# MIMXRT1011 register map
Vendor: nxp.com; File version: 1.0
CPU: CM7 r0p1, little endian, MPU, FPU, VTOR, 4 interrupt priority bits
Registers are 32-bit, read-write, reset 0x0 unless marked. A register's access mark holds for its fields unless they carry their own. Offsets are from the block's base; [hi:lo] are bit positions; {n}, {i} and the like mark numbered series; 'fields as' and 'values as' point back to an identical list.

## IOMUXC_GPR
Base 0x400AC000; register names take the prefix IOMUXC_GPR_
0x00 GPR0 ro — GPR0 General Purpose Register
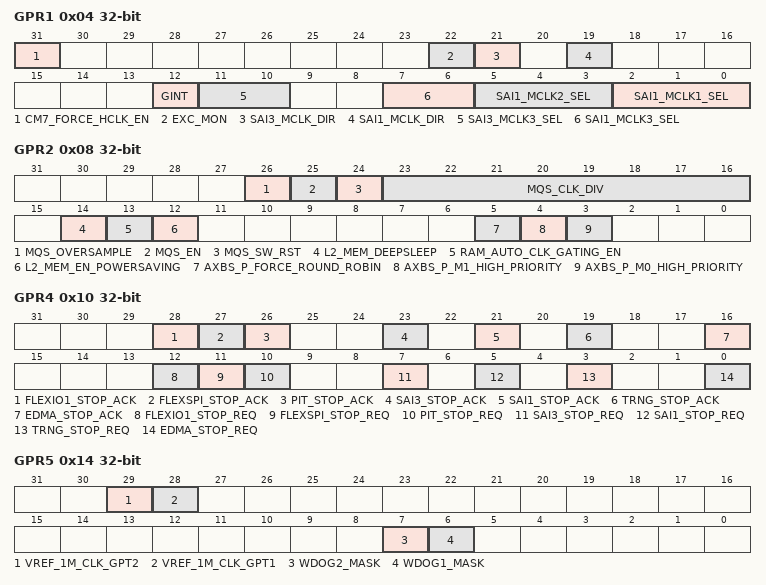
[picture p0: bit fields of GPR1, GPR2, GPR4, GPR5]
0x04 GPR1 — GPR1 General Purpose Register
  [31] CM7_FORCE_HCLK_EN — Arm CM7 platform AHB clock enable
    0=AHB clock is not running (gated) when CM7 is sleeping and TCM is not accessible; 1=AHB clock is running (enabled) when CM7 is sleeping and TCM is accessible
  [22] EXC_MON — Exclusive monitor response select of illegal command
    0=OKAY response; 1=SLVError response
  [21] SAI3_MCLK_DIR — sai3.MCLK signal direction control
    0=sai3.MCLK is input signal; 1=sai3.MCLK is output signal
  [19] SAI1_MCLK_DIR — sai1.MCLK signal direction control
    0=sai1.MCLK is input signal; 1=sai1.MCLK is output signal
  [12] GINT — Global Interrupt
    0=Global interrupt request is not asserted; 1=Global interrupt request is asserted
  [11:10] SAI3_MCLK3_SEL — SAI3 MCLK3 source select
    0=ccm.spdif0_clk_root; 1=SPDIF_EXT_CLK; 2=spdif.spdif_srclk; 3=spdif.spdif_outclock
  [7:6] SAI1_MCLK3_SEL — SAI1 MCLK3 source select
    values as SAI3_MCLK3_SEL
  [5:3] SAI1_MCLK2_SEL — SAI1 MCLK2 source select
    0=ccm.ssi1_clk_root; 2=ccm.ssi3_clk_root; 3=iomux.sai1_ipg_clk_sai_mclk; 5=iomux.sai3_ipg_clk_sai_mclk
  [2:0] SAI1_MCLK1_SEL — SAI1 MCLK1 source select
    values as SAI1_MCLK2_SEL
0x08 GPR2 — GPR2 General Purpose Register
  [26] MQS_OVERSAMPLE — Medium Quality Sound (MQS) Oversample
    0=32; 1=64
  [25] MQS_EN — MQS enable.
    0=Disable MQS; 1=Enable MQS
  [24] MQS_SW_RST — MQS software reset
    0=Exit software reset for MQS; 1=Enable software reset for MQS
  [23:16] MQS_CLK_DIV — Divider ratio control for mclk from hmclk
    0=mclk frequency = hmclk frequency; 1=mclk frequency = 1/2 * hmclk frequency; 2=mclk frequency = 1/3 * hmclk frequency; 255=mclk frequency = 1/256 * hmclk frequency
  [14] L2_MEM_DEEPSLEEP — This bit controls how memory (OCRAM) enters Deep Sleep mode (shutdown periphery power, but maintain memory contents, outputs of memory are pulled low
    0=No force sleep control supported, memory deep sleep mode only entered when whole system in stop mode (OCRAM in normal mode); 1=Force memory into deep sleep mode (OCRAM in power saving mode)
  [13] RAM_AUTO_CLK_GATING_EN — Automatically gate off RAM clock when RAM is not accessed.
    0=disable automatically gate off RAM clock; 1=enable automatically gate off RAM clock
  [12] L2_MEM_EN_POWERSAVING — Enable power saving features on L2 memory
    0=Enters power saving mode only when chip is in SUSPEND mode; 1=Controlled by L2_MEM_DEEPSLEEP bitfield
  [5] AXBS_P_FORCE_ROUND_ROBIN — Force Round Robin in AXBS_P. This bit can override master M0 M1 high priority configuration.
    0=AXBS_P masters are not arbitored in round robin, depending on M0/M1 master priority settings; 1=AXBS_P masters are arbitored in round robin
  [4] AXBS_P_M1_HIGH_PRIORITY — AXBS_P M1 master has higher priority.Do not set both M1 and M0 to high priority.
    0=AXBS_P M1 master does not have high priority; 1=AXBS_P M1 master has high priority
  [3] AXBS_P_M0_HIGH_PRIORITY — AXBS_P M0 master has higher priority.Do not set both M1 and M0 to high priority.
    0=AXBS_P M0 master doesn't have high priority; 1=AXBS_P M0 master has high priority
0x0C GPR3 reset 0xFF0 — GPR3 General Purpose Register
  [4] DCP_KEY_SEL — Select 128-bit DCP key from 256-bit key from SNVS Master Key
    0=Select [127:0] from SNVS Master Key as DCP key; 1=Select [255:128] from SNVS Master Key as DCP key
0x10 GPR4 — GPR4 General Purpose Register
  [28] FLEXIO1_STOP_ACK ro — FLEXIO1 stop acknowledge
    0=FLEXIO1 stop acknowledge is not asserted; 1=FLEXIO1 stop acknowledge is asserted
  [27] FLEXSPI_STOP_ACK ro — FLEXSPI stop acknowledge
    0=FLEXSPI stop acknowledge is not asserted; 1=FLEXSPI stop acknowledge is asserted
  [26] PIT_STOP_ACK ro — PIT stop acknowledge
    0=PIT stop acknowledge is not asserted; 1=PIT stop acknowledge is asserted
  [23] SAI3_STOP_ACK ro — SAI3 stop acknowledge
    0=SAI3 stop acknowledge is not asserted; 1=SAI3 stop acknowledge is asserted
  [21] SAI1_STOP_ACK ro — SAI1 stop acknowledge
    0=SAI1 stop acknowledge is not asserted; 1=SAI1 stop acknowledge is asserted
  [19] TRNG_STOP_ACK ro — TRNG stop acknowledge
    0=TRNG stop acknowledge is not asserted; 1=TRNG stop acknowledge is asserted
  [16] EDMA_STOP_ACK ro — EDMA stop acknowledge. This is a status (read-only) bit
    0=EDMA stop acknowledge is not asserted; 1=EDMA stop acknowledge is asserted (EDMA is in STOP mode)
  [12] FLEXIO1_STOP_REQ — FlexIO1 stop request.
    0=stop request off; 1=stop request on
  [11] FLEXSPI_STOP_REQ — FlexSPI stop request.
    0=stop request off; 1=stop request on
  [10] PIT_STOP_REQ — PIT stop request.
    0=stop request off; 1=stop request on
  [7] SAI3_STOP_REQ — SAI3 stop request.
    0=stop request off; 1=stop request on
  [5] SAI1_STOP_REQ — SAI1 stop request.
    0=stop request off; 1=stop request on
  [3] TRNG_STOP_REQ — TRNG stop request.
    0=stop request off; 1=stop request on
  [0] EDMA_STOP_REQ — EDMA stop request.
    0=stop request off; 1=stop request on
0x14 GPR5 — GPR5 General Purpose Register
  [29] VREF_1M_CLK_GPT2 — GPT2 1 MHz clock source select
    0=GPT2 ipg_clk_highfreq driven by IPG_PERCLK; 1=GPT2 ipg_clk_highfreq driven by anatop 1 MHz clock
  [28] VREF_1M_CLK_GPT1 — GPT1 1 MHz clock source select
    0=GPT1 ipg_clk_highfreq driven by IPG_PERCLK; 1=GPT1 ipg_clk_highfreq driven by anatop 1 MHz clock
  [7] WDOG2_MASK — WDOG2 Timeout Mask
    0=WDOG2 Timeout behaves normally; 1=WDOG2 Timeout is masked
  [6] WDOG1_MASK — WDOG1 Timeout Mask
    0=WDOG1 Timeout behaves normally; 1=WDOG1 Timeout is masked
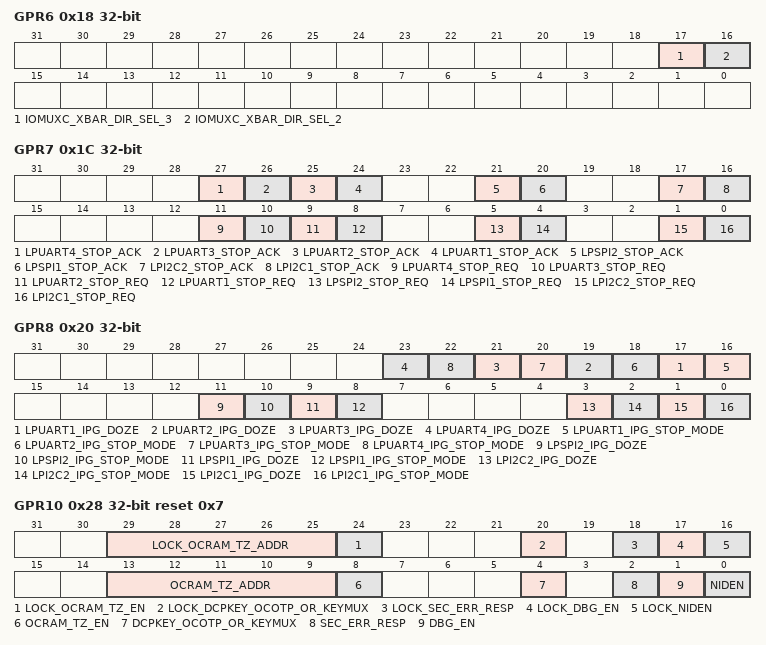
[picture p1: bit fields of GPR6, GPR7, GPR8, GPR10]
0x18 GPR6 — GPR6 General Purpose Register
  [17] IOMUXC_XBAR_DIR_SEL_3 — IOMUXC XBAR_INOUT3 function direction select
    0=XBAR_INOUT as input; 1=XBAR_INOUT as output
  [16] IOMUXC_XBAR_DIR_SEL_2 — IOMUXC XBAR_INOUT2 function direction select
    0=XBAR_INOUT as input; 1=XBAR_INOUT as output
0x1C GPR7 — GPR7 General Purpose Register
  [27] LPUART4_STOP_ACK ro — LPUART4 stop acknowledge
    0=stop acknowledge is not asserted; 1=stop acknowledge is asserted
  [26] LPUART3_STOP_ACK ro — LPUART3 stop acknowledge
    values as LPUART4_STOP_ACK
  [25] LPUART2_STOP_ACK ro — LPUART1 stop acknowledge
    values as LPUART4_STOP_ACK
  [24] LPUART1_STOP_ACK ro — LPUART1 stop acknowledge
    values as LPUART4_STOP_ACK
  [21] LPSPI2_STOP_ACK ro — LPSPI2 stop acknowledge
    values as LPUART4_STOP_ACK
  [20] LPSPI1_STOP_ACK ro — LPSPI1 stop acknowledge
    values as LPUART4_STOP_ACK
  [17] LPI2C2_STOP_ACK ro — LPI2C2 stop acknowledge
    values as LPUART4_STOP_ACK
  [16] LPI2C1_STOP_ACK ro — LPI2C1 stop acknowledge
    0=stop acknowledge is not asserted; 1=stop acknowledge is asserted (the module is in Stop mode)
  [11] LPUART4_STOP_REQ — LPUART4 stop request
    0=stop request off; 1=stop request on
  [10] LPUART3_STOP_REQ — LPUART3 stop request
    0=stop request off; 1=stop request on
  [9] LPUART2_STOP_REQ — LPUART1 stop request
    0=stop request off; 1=stop request on
  [8] LPUART1_STOP_REQ — LPUART1 stop request
    0=stop request off; 1=stop request on
  [5] LPSPI2_STOP_REQ — LPSPI2 stop request
    0=stop request off; 1=stop request on
  [4] LPSPI1_STOP_REQ — LPSPI1 stop request
    0=stop request off; 1=stop request on
  [1] LPI2C2_STOP_REQ — LPI2C2 stop request
    0=stop request off; 1=stop request on
  [0] LPI2C1_STOP_REQ — LPI2C1 stop request
    0=stop request off; 1=stop request on
0x20 GPR8 — GPR8 General Purpose Register
  [2n+15] LPUART{n}_IPG_DOZE (n=1..4) — LPUART{n} ipg_doze mode
    0=not in doze mode; 1=in doze mode
  [2n+14] LPUART{n}_IPG_STOP_MODE (n=1..4) — LPUART{n} stop mode selection, cannot change when ipg_stop is asserted.
    0=the module is functional in Stop mode; 1=the module is NOT functional in Stop mode, when this bit is equal to 1 and ipg_stop is asserted
  [11] LPSPI2_IPG_DOZE — LPSPI2 ipg_doze mode
    0=not in doze mode; 1=in doze mode
  [10] LPSPI2_IPG_STOP_MODE — LPSPI2 stop mode selection, cannot change when ipg_stop is asserted.
    values as LPUART1_IPG_STOP_MODE
  [9] LPSPI1_IPG_DOZE — LPSPI1 ipg_doze mode
    0=not in doze mode; 1=in doze mode
  [8] LPSPI1_IPG_STOP_MODE — LPSPI1 stop mode selection, cannot change when ipg_stop is asserted.
    values as LPUART1_IPG_STOP_MODE
  [3] LPI2C2_IPG_DOZE — LPI2C2 ipg_doze mode
    0=not in doze mode; 1=in doze mode
  [2] LPI2C2_IPG_STOP_MODE — LPI2C2 stop mode selection, cannot change when ipg_stop is asserted.
    values as LPUART1_IPG_STOP_MODE
  [1] LPI2C1_IPG_DOZE — LPI2C1 ipg_doze mode
    0=not in doze mode; 1=in doze mode
  [0] LPI2C1_IPG_STOP_MODE — LPI2C1 stop mode selection, cannot change when ipg_stop is asserted.
    values as LPUART1_IPG_STOP_MODE
0x24 GPR9 ro — GPR9 General Purpose Register
0x28 GPR10 reset 0x7 — GPR10 General Purpose Register
  [29:25] LOCK_OCRAM_TZ_ADDR — Lock OCRAM_TZ_ADDR field for changes
    0=Field is not locked; 1=Field is locked (read access only)
  [24] LOCK_OCRAM_TZ_EN — Lock OCRAM_TZ_EN field for changes
    0=Field is not locked; 1=Field is locked (read access only)
  [20] LOCK_DCPKEY_OCOTP_OR_KEYMUX — Lock DCP Key OCOTP/Key MUX selection bit
    0=Field is not locked; 1=Field is locked (read access only)
  [18] LOCK_SEC_ERR_RESP — Lock SEC_ERR_RESP field for changes
    0=Field is not locked; 1=Field is locked (read access only)
  [17] LOCK_DBG_EN — Lock DBG_EN field for changes
    0=Field is not locked; 1=Field is locked (read access only)
  [16] LOCK_NIDEN — Lock NIDEN field for changes
    0=Field is not locked; 1=Field is locked (read access only)
  [13:9] OCRAM_TZ_ADDR — OCRAM TrustZone (TZ) start address
  [8] OCRAM_TZ_EN — OCRAM TrustZone (TZ) enable.
    0=The TrustZone feature is disabled. Entire OCRAM space is available for all access types (secure/non-secure/user/supervisor).; 1=The TrustZone feature is enabled. Access to address in the range specified by [ENDADDR:STARTADDR] follows the execution mode access policy described in CSU chapter.
  [4] DCPKEY_OCOTP_OR_KEYMUX — DCP Key selection bit.
    0=Select key from SNVS Master Key; 1=Select key from OCOTP (SW_GP2)
  [2] SEC_ERR_RESP — Security error response enable for all security gaskets (on both AHB and AXI buses)
    0=OKEY response; 1=SLVError (default)
  [1] DBG_EN — Arm invasive debug enable
    0=Debug turned off; 1=Debug enabled (default)
  [0] NIDEN — Arm non-secure (non-invasive) debug enable
    0=Debug turned off; 1=Debug enabled (default)
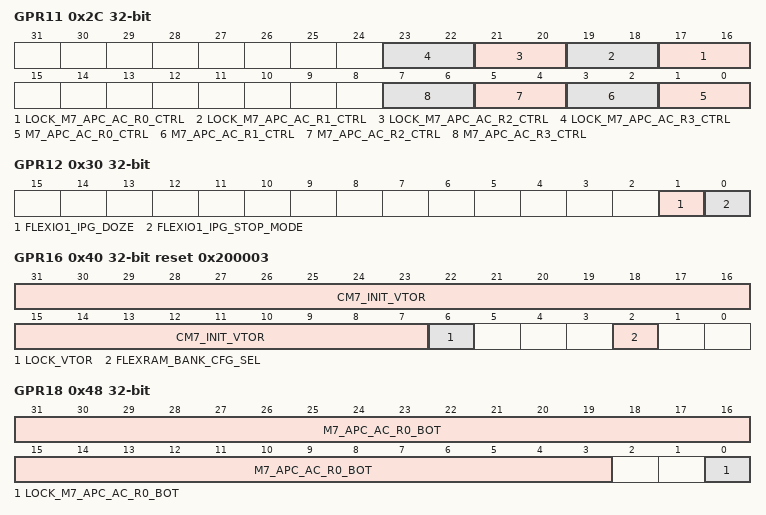
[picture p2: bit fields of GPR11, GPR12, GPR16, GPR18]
0x2C GPR11 — GPR11 General Purpose Register
  [2n+17:2n+16] LOCK_M7_APC_AC_R{n}_CTRL (n=0..3) — Lock M7_APC_AC_R{n}_CTRL field for changes
  [2n+1:2n] M7_APC_AC_R{n}_CTRL (n=0..3) — Access control of memory region-{n}
    0=No access protection; 1=M7 debug protection enabled
0x30 GPR12 — GPR12 General Purpose Register
  [1] FLEXIO1_IPG_DOZE — FLEXIO1 ipg_doze mode
    0=FLEXIO1 is not in doze mode; 1=FLEXIO1 is in doze mode
  [0] FLEXIO1_IPG_STOP_MODE — FlexIO1 stop mode selection. Cannot change when ipg_stop is asserted.
    0=FlexIO1 is functional in Stop mode; 1=When this bit is equal to 1'b1 and ipg_stop is asserted, FlexIO1 is not functional in Stop mode
0x34 GPR13 — GPR13 General Purpose Register
  [13] CACHE_USB — USB block cacheable attribute value of AXI transactions
    0=Cacheable attribute is off for read/write transactions; 1=Cacheable attribute is on for read/write transactions
0x38 GPR14 ro reset 0x880000 — GPR14 General Purpose Register
0x3C GPR15 ro reset 0xFFFFFFFF — GPR15 General Purpose Register
0x40 GPR16 reset 0x200003 — GPR16 General Purpose Register
  [31:7] CM7_INIT_VTOR — Vector table offset register out of reset
  [6] LOCK_VTOR — Lock CM7_INIT_VTOR field for changes
    0=CM7_INIT_VTOR field is not locked; 1=CM7_INIT_VTOR field is locked (read access only)
  [2] FLEXRAM_BANK_CFG_SEL — FlexRAM bank config source select
    0=use fuse value to config; 1=use FLEXRAM_BANK_CFG to config
0x44 GPR17 — GPR17 General Purpose Register
  [7:0] FLEXRAM_BANK_CFG — FlexRAM bank config value
0x48 GPR18 — GPR18 General Purpose Register
  [31:3] M7_APC_AC_R0_BOT — APC end address of memory region-0
  [0] LOCK_M7_APC_AC_R0_BOT — lock M7_APC_AC_R0_BOT field for changes
    0=Register field [31:1] is not locked; 1=Register field [31:1] is locked (read access only)
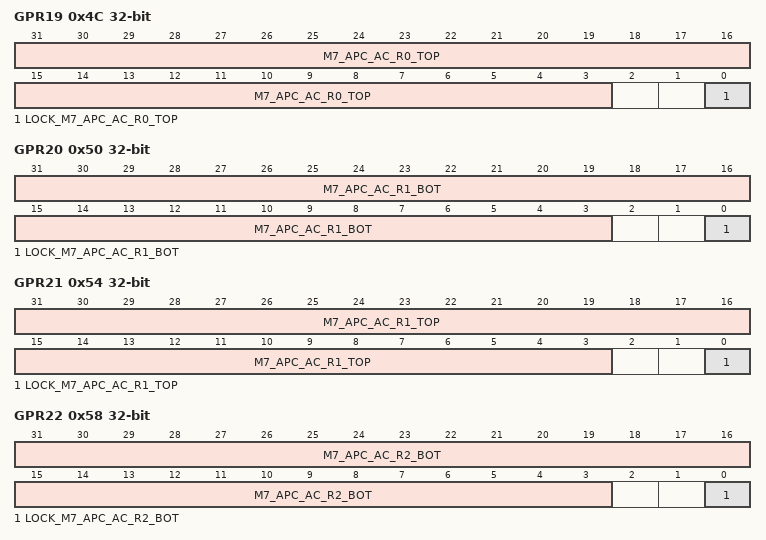
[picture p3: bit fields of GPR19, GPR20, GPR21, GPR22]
0x4C GPR19 — GPR19 General Purpose Register
  [31:3] M7_APC_AC_R0_TOP — APC start address of memory region-0
  [0] LOCK_M7_APC_AC_R0_TOP — lock M7_APC_AC_R0_TOP field for changes
    values as GPR18.LOCK_M7_APC_AC_R0_BOT
0x50 GPR20 — GPR20 General Purpose Register
  [31:3] M7_APC_AC_R1_BOT — APC end address of memory region-1
  [0] LOCK_M7_APC_AC_R1_BOT — lock M7_APC_AC_R1_BOT field for changes
    values as GPR18.LOCK_M7_APC_AC_R0_BOT
0x54 GPR21 — GPR21 General Purpose Register
  [31:3] M7_APC_AC_R1_TOP — APC start address of memory region-1
  [0] LOCK_M7_APC_AC_R1_TOP — lock M7_APC_AC_R1_TOP field for changes
    values as GPR18.LOCK_M7_APC_AC_R0_BOT
0x58 GPR22 — GPR22 General Purpose Register
  [31:3] M7_APC_AC_R2_BOT — APC end address of memory region-2
  [0] LOCK_M7_APC_AC_R2_BOT — lock M7_APC_AC_R2_BOT field for changes
    values as GPR18.LOCK_M7_APC_AC_R0_BOT
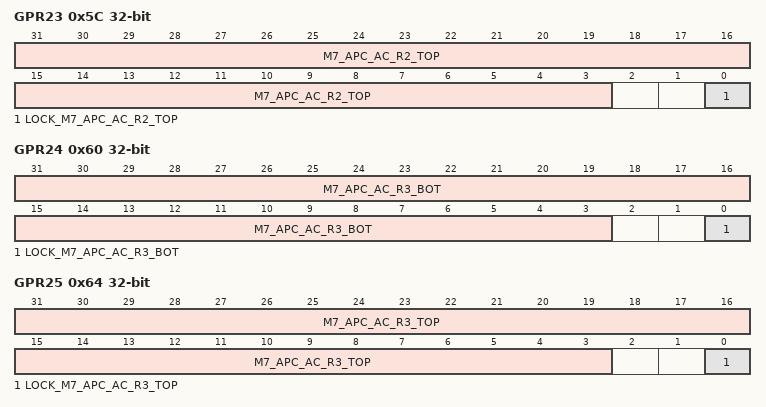
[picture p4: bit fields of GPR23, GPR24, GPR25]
0x5C GPR23 — GPR23 General Purpose Register
  [31:3] M7_APC_AC_R2_TOP — APC start address of memory region-2
  [0] LOCK_M7_APC_AC_R2_TOP — lock M7_APC_AC_R2_TOP field for changes
    values as GPR18.LOCK_M7_APC_AC_R0_BOT
0x60 GPR24 — GPR24 General Purpose Register
  [31:3] M7_APC_AC_R3_BOT — APC end address of memory region-3
  [0] LOCK_M7_APC_AC_R3_BOT — lock M7_APC_AC_R3_BOT field for changes
    values as GPR18.LOCK_M7_APC_AC_R0_BOT
0x64 GPR25 — GPR25 General Purpose Register
  [31:3] M7_APC_AC_R3_TOP — APC start address of memory region-3
  [0] LOCK_M7_APC_AC_R3_TOP — lock M7_APC_AC_R3_TOP field for changes
    values as GPR18.LOCK_M7_APC_AC_R0_BOT
0x68 GPR26 — GPR26 General Purpose Register
  [31:0] GPIO_SEL — Select GPIO1 or GPIO2
0x6C GPR27 — GPR27 General Purpose Register
  [31:12] FLEXSPI_REMAP_ADDR_START — Start address of flexspi1
0x70 GPR28 — GPR28 General Purpose Register
  [31:12] FLEXSPI_REMAP_ADDR_END — End address of flexspi1
0x74 GPR29 — GPR29 General Purpose Register
  [31:12] FLEXSPI_REMAP_ADDR_OFFSET — Offset address of flexspi1
